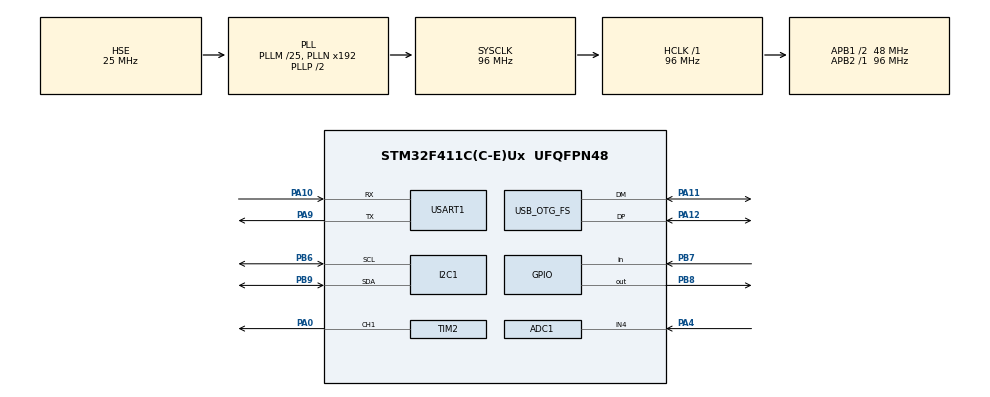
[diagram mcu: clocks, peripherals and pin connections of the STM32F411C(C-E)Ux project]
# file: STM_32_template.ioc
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ADC1.Channel-3\#ChannelRegularConversion=ADC_CHANNEL_4
ADC1.Channel-6\#ChannelInjectedConversion=ADC_CHANNEL_4
ADC1.Channel-7\#ChannelInjectedConversion=ADC_CHANNEL_4
ADC1.Channel-8\#ChannelInjectedConversion=ADC_CHANNEL_4
ADC1.Channel-9\#ChannelInjectedConversion=ADC_CHANNEL_4
ADC1.ContinuousConvMode=ENABLE
ADC1.DMAContinuousRequests=ENABLE
ADC1.DiscontinuousConvMode=DISABLE
ADC1.InjNumberOfConversion=4
ADC1.InjectedOffset-6\#ChannelInjectedConversion=0
ADC1.InjectedOffset-7\#ChannelInjectedConversion=0
ADC1.InjectedOffset-8\#ChannelInjectedConversion=0
ADC1.InjectedOffset-9\#ChannelInjectedConversion=0
ADC1.InjectedRank-6\#ChannelInjectedConversion=1
ADC1.InjectedRank-7\#ChannelInjectedConversion=2
ADC1.InjectedRank-8\#ChannelInjectedConversion=3
ADC1.InjectedRank-9\#ChannelInjectedConversion=4
ADC1.NbrOfConversion=1
ADC1.NbrOfConversionFlag=1
ADC1.Rank-3\#ChannelRegularConversion=1
ADC1.Resolution=ADC_RESOLUTION_12B
ADC1.SamplingTime-3\#ChannelRegularConversion=ADC_SAMPLETIME_3CYCLES
ADC1.SamplingTime-6\#ChannelInjectedConversion=ADC_SAMPLETIME_3CYCLES
ADC1.SamplingTime-7\#ChannelInjectedConversion=ADC_SAMPLETIME_3CYCLES
ADC1.SamplingTime-8\#ChannelInjectedConversion=ADC_SAMPLETIME_3CYCLES
ADC1.SamplingTime-9\#ChannelInjectedConversion=ADC_SAMPLETIME_3CYCLES
ADC1.ScanConvMode=ENABLE
ADC1.master=1
Dma.ADC1.0.Direction=DMA_PERIPH_TO_MEMORY
Dma.ADC1.0.FIFOMode=DMA_FIFOMODE_ENABLE
Dma.ADC1.0.FIFOThreshold=DMA_FIFO_THRESHOLD_FULL
Dma.ADC1.0.Instance=DMA2_Stream0
Dma.ADC1.0.MemBurst=DMA_MBURST_SINGLE
Dma.ADC1.0.MemDataAlignment=DMA_MDATAALIGN_WORD
Dma.ADC1.0.MemInc=DMA_MINC_ENABLE
Dma.ADC1.0.Mode=DMA_CIRCULAR
Dma.ADC1.0.PeriphBurst=DMA_PBURST_SINGLE
Dma.ADC1.0.PeriphDataAlignment=DMA_PDATAALIGN_WORD
Dma.ADC1.0.PeriphInc=DMA_PINC_DISABLE
Dma.ADC1.0.Priority=DMA_PRIORITY_LOW
Dma.Request0=ADC1
Dma.Request1=USART1_TX
Dma.USART1_TX.1.Direction=DMA_MEMORY_TO_PERIPH
Dma.USART1_TX.1.FIFOMode=DMA_FIFOMODE_ENABLE
Dma.USART1_TX.1.FIFOThreshold=DMA_FIFO_THRESHOLD_FULL
Dma.USART1_TX.1.Instance=DMA2_Stream7
Dma.USART1_TX.1.MemBurst=DMA_MBURST_SINGLE
Dma.USART1_TX.1.MemDataAlignment=DMA_MDATAALIGN_BYTE
Dma.USART1_TX.1.MemInc=DMA_MINC_ENABLE
Dma.USART1_TX.1.Mode=DMA_NORMAL
Dma.USART1_TX.1.PeriphBurst=DMA_PBURST_SINGLE
Dma.USART1_TX.1.PeriphDataAlignment=DMA_PDATAALIGN_BYTE
Dma.USART1_TX.1.PeriphInc=DMA_PINC_DISABLE
Dma.USART1_TX.1.Priority=DMA_PRIORITY_LOW
Mcu.Family=STM32F4
Mcu.Name=STM32F411C(C-E)Ux
Mcu.Package=UFQFPN48
NVIC.ADC_IRQn=true\:0\:0\:false\:false\:true\:true\:true\:true
NVIC.DMA2_Stream0_IRQn=true\:0\:0\:false\:false\:true\:false\:true\:true
NVIC.DMA2_Stream7_IRQn=true\:0\:0\:false\:false\:true\:false\:true\:true
NVIC.OTG_FS_IRQn=true\:0\:0\:false\:false\:true\:false\:true\:true
NVIC.PriorityGroup=NVIC_PRIORITYGROUP_4
NVIC.USART1_IRQn=true\:0\:0\:false\:false\:true\:true\:true\:true
PA0-WKUP.Signal=S_TIM2_CH1_ETR
PA10.Mode=Asynchronous
PA10.Signal=USART1_RX
PA11.Mode=Device_Only
PA11.Signal=USB_OTG_FS_DM
PA12.Mode=Device_Only
PA12.Signal=USB_OTG_FS_DP
PA4.Signal=ADCx_IN4
PA9.Mode=Asynchronous
PA9.Signal=USART1_TX
PB6.Mode=I2C
PB6.Signal=I2C1_SCL
PB7.GPIO_PuPd=GPIO_PULLUP
PB7.Signal=GPIO_Input
PB8.Signal=GPIO_Output
PB9.Mode=I2C
PB9.Signal=I2C1_SDA
PH0\ -\ OSC_IN.Mode=HSE-External-Oscillator
PH0\ -\ OSC_IN.Signal=RCC_OSC_IN
PH1\ -\ OSC_OUT.Mode=HSE-External-Oscillator
PH1\ -\ OSC_OUT.Signal=RCC_OSC_OUT
ProjectManager.HeapSize=0x200
ProjectManager.StackSize=0x400
ProjectManager.TargetToolchain=STM32CubeIDE
RCC.48MHZClocksFreq_Value=48000000
RCC.AHBFreq_Value=96000000
RCC.APB1CLKDivider=RCC_HCLK_DIV2
RCC.APB1Freq_Value=48000000
RCC.APB1TimFreq_Value=96000000
RCC.APB2Freq_Value=96000000
RCC.APB2TimFreq_Value=96000000
RCC.CortexFreq_Value=96000000
RCC.HCLKFreq_Value=96000000
RCC.HSE_VALUE=25000000
RCC.HSI_VALUE=16000000
RCC.LSE_VALUE=32768
RCC.PLLM=25
RCC.SYSCLKFreq_VALUE=96000000
RCC.SYSCLKSource=RCC_SYSCLKSOURCE_PLLCLK
RCC.VCOOutputFreq_Value=192000000
SH.ADCx_IN4.0=ADC1_IN4,IN4
SH.S_TIM2_CH1_ETR.0=TIM2_CH1,PWM Generation1 CH1
TIM2.Channel-PWM\ Generation1\ CH1=TIM_CHANNEL_1
TIM2.Period=49
TIM2.Prescaler=95
TIM2.Pulse-PWM\ Generation1\ CH1=500
USART1.Parity=PARITY_NONE
USART1.StopBits=STOPBITS_1
USART1.VirtualMode=VM_ASYNC
USB_DEVICE.CLASS_NAME_FS=CDC
USB_DEVICE.VirtualMode=Cdc
USB_DEVICE.VirtualModeFS=Cdc_FS
USB_OTG_FS.VirtualMode=Device_Only
VP_USB_DEVICE_VS_USB_DEVICE_CDC_FS.Mode=CDC_FS
board=custom

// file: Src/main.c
/* USER CODE BEGIN Header */
/**
  ******************************************************************************
  * @file           : main.c
  * @brief          : Main program body
  ******************************************************************************
  * @attention
  *
  * Copyright (c) 2026 STMicroelectronics.
  * All rights reserved.
  *
  * This software is licensed under terms that can be found in the LICENSE file
  * in the root directory of this software component.
  * If no LICENSE file comes with this software, it is provided AS-IS.
  *
  ******************************************************************************
  */
/* USER CODE END Header */
#include "main.h"
#include "usb_device.h"

/* USER CODE BEGIN Includes */
#include <stdio.h>
#include "app/main_app.h"

/* USER CODE END Includes */

ADC_HandleTypeDef hadc1;
DMA_HandleTypeDef hdma_adc1;

I2C_HandleTypeDef hi2c1;

TIM_HandleTypeDef htim2;

UART_HandleTypeDef huart1;
DMA_HandleTypeDef hdma_usart1_tx;

void SystemClock_Config(void);
static void MX_GPIO_Init(void);
static void MX_DMA_Init(void);
static void MX_ADC1_Init(void);
static void MX_TIM2_Init(void);
static void MX_USART1_UART_Init(void);
static void MX_I2C1_Init(void);

int main(void)
{

  /* MCU Configuration--------------------------------------------------------*/

  /* Reset of all peripherals, Initializes the Flash interface and the Systick. */
  HAL_Init();

  /* Configure the system clock */
  SystemClock_Config();

  /* Initialize all configured peripherals */
  MX_GPIO_Init();
  MX_DMA_Init();
  MX_USB_DEVICE_Init();
  MX_ADC1_Init();
  MX_TIM2_Init();
  MX_USART1_UART_Init();
  MX_I2C1_Init();
  /* USER CODE BEGIN 2 */

   if (main_cpp != NULL)
  {
    main_cpp();
  }

  /* USER CODE END 2 */

  /* Infinite loop */
  /* USER CODE BEGIN WHILE */
  while (1)
  {
    printf("HELLO FROM STM32\r\n");
     HAL_Delay(1000);
    /* USER CODE END WHILE */

  }
}

void SystemClock_Config(void)
{
  RCC_OscInitTypeDef RCC_OscInitStruct = {0};
  RCC_ClkInitTypeDef RCC_ClkInitStruct = {0};

  /** Configure the main internal regulator output voltage
  */
  __HAL_RCC_PWR_CLK_ENABLE();
  __HAL_PWR_VOLTAGESCALING_CONFIG(PWR_REGULATOR_VOLTAGE_SCALE1);

  /** Initializes the RCC Oscillators according to the specified parameters
  * in the RCC_OscInitTypeDef structure.
  */
  RCC_OscInitStruct.OscillatorType = RCC_OSCILLATORTYPE_HSE;
  RCC_OscInitStruct.HSEState = RCC_HSE_ON;
  RCC_OscInitStruct.PLL.PLLState = RCC_PLL_ON;
  RCC_OscInitStruct.PLL.PLLSource = RCC_PLLSOURCE_HSE;
  RCC_OscInitStruct.PLL.PLLM = 25;
  RCC_OscInitStruct.PLL.PLLN = 192;
  RCC_OscInitStruct.PLL.PLLP = RCC_PLLP_DIV2;
  RCC_OscInitStruct.PLL.PLLQ = 4;
  if (HAL_RCC_OscConfig(&RCC_OscInitStruct) != HAL_OK)
  {
    Error_Handler();
  }

  /** Initializes the CPU, AHB and APB buses clocks
  */
  RCC_ClkInitStruct.ClockType = RCC_CLOCKTYPE_HCLK|RCC_CLOCKTYPE_SYSCLK
                              |RCC_CLOCKTYPE_PCLK1|RCC_CLOCKTYPE_PCLK2;
  RCC_ClkInitStruct.SYSCLKSource = RCC_SYSCLKSOURCE_PLLCLK;
  RCC_ClkInitStruct.AHBCLKDivider = RCC_SYSCLK_DIV1;
  RCC_ClkInitStruct.APB1CLKDivider = RCC_HCLK_DIV2;
  RCC_ClkInitStruct.APB2CLKDivider = RCC_HCLK_DIV1;

  if (HAL_RCC_ClockConfig(&RCC_ClkInitStruct, FLASH_LATENCY_3) != HAL_OK)
  {
    Error_Handler();
  }
}

static void MX_ADC1_Init(void)
{

  ADC_ChannelConfTypeDef sConfig = {0};
  ADC_InjectionConfTypeDef sConfigInjected = {0};

  /** Configure the global features of the ADC (Clock, Resolution, Data Alignment and number of conversion)
  */
  hadc1.Instance = ADC1;
  hadc1.Init.ClockPrescaler = ADC_CLOCK_SYNC_PCLK_DIV4;
  hadc1.Init.Resolution = ADC_RESOLUTION_12B;
  hadc1.Init.ScanConvMode = ENABLE;
  hadc1.Init.ContinuousConvMode = ENABLE;
  hadc1.Init.DiscontinuousConvMode = DISABLE;
  hadc1.Init.ExternalTrigConvEdge = ADC_EXTERNALTRIGCONVEDGE_NONE;
  hadc1.Init.ExternalTrigConv = ADC_SOFTWARE_START;
  hadc1.Init.DataAlign = ADC_DATAALIGN_RIGHT;
  hadc1.Init.NbrOfConversion = 1;
  hadc1.Init.DMAContinuousRequests = ENABLE;
  hadc1.Init.EOCSelection = ADC_EOC_SINGLE_CONV;
  if (HAL_ADC_Init(&hadc1) != HAL_OK)
  {
    Error_Handler();
  }

  /** Configure for the selected ADC regular channel its corresponding rank in the sequencer and its sample time.
  */
  sConfig.Channel = ADC_CHANNEL_4;
  sConfig.Rank = 1;
  sConfig.SamplingTime = ADC_SAMPLETIME_3CYCLES;
  if (HAL_ADC_ConfigChannel(&hadc1, &sConfig) != HAL_OK)
  {
    Error_Handler();
  }

  /** Configures for the selected ADC injected channel its corresponding rank in the sequencer and its sample time
  */
  sConfigInjected.InjectedChannel = ADC_CHANNEL_4;
  sConfigInjected.InjectedRank = 1;
  sConfigInjected.InjectedNbrOfConversion = 4;
  sConfigInjected.InjectedSamplingTime = ADC_SAMPLETIME_3CYCLES;
  sConfigInjected.ExternalTrigInjecConvEdge = ADC_EXTERNALTRIGINJECCONVEDGE_NONE;
  sConfigInjected.ExternalTrigInjecConv = ADC_INJECTED_SOFTWARE_START;
  sConfigInjected.AutoInjectedConv = DISABLE;
  sConfigInjected.InjectedDiscontinuousConvMode = DISABLE;
  sConfigInjected.InjectedOffset = 0;
  if (HAL_ADCEx_InjectedConfigChannel(&hadc1, &sConfigInjected) != HAL_OK)
  {
    Error_Handler();
  }

  /** Configures for the selected ADC injected channel its corresponding rank in the sequencer and its sample time
  */
  sConfigInjected.InjectedRank = 2;
  if (HAL_ADCEx_InjectedConfigChannel(&hadc1, &sConfigInjected) != HAL_OK)
  {
    Error_Handler();
  }

  /** Configures for the selected ADC injected channel its corresponding rank in the sequencer and its sample time
  */
  sConfigInjected.InjectedRank = 3;
  if (HAL_ADCEx_InjectedConfigChannel(&hadc1, &sConfigInjected) != HAL_OK)
  {
    Error_Handler();
  }

  /** Configures for the selected ADC injected channel its corresponding rank in the sequencer and its sample time
  */
  sConfigInjected.InjectedRank = 4;
  if (HAL_ADCEx_InjectedConfigChannel(&hadc1, &sConfigInjected) != HAL_OK)
  {
    Error_Handler();
  }

}

static void MX_I2C1_Init(void)
{

  hi2c1.Instance = I2C1;
  hi2c1.Init.ClockSpeed = 100000;
  hi2c1.Init.DutyCycle = I2C_DUTYCYCLE_2;
  hi2c1.Init.OwnAddress1 = 0;
  hi2c1.Init.AddressingMode = I2C_ADDRESSINGMODE_7BIT;
  hi2c1.Init.DualAddressMode = I2C_DUALADDRESS_DISABLE;
  hi2c1.Init.OwnAddress2 = 0;
  hi2c1.Init.GeneralCallMode = I2C_GENERALCALL_DISABLE;
  hi2c1.Init.NoStretchMode = I2C_NOSTRETCH_DISABLE;
  if (HAL_I2C_Init(&hi2c1) != HAL_OK)
  {
    Error_Handler();
  }

}

static void MX_TIM2_Init(void)
{

  TIM_MasterConfigTypeDef sMasterConfig = {0};
  TIM_OC_InitTypeDef sConfigOC = {0};

  htim2.Instance = TIM2;
  htim2.Init.Prescaler = 95;
  htim2.Init.CounterMode = TIM_COUNTERMODE_UP;
  htim2.Init.Period = 49;
  htim2.Init.ClockDivision = TIM_CLOCKDIVISION_DIV1;
  htim2.Init.AutoReloadPreload = TIM_AUTORELOAD_PRELOAD_DISABLE;
  if (HAL_TIM_PWM_Init(&htim2) != HAL_OK)
  {
    Error_Handler();
  }
  sMasterConfig.MasterOutputTrigger = TIM_TRGO_RESET;
  sMasterConfig.MasterSlaveMode = TIM_MASTERSLAVEMODE_DISABLE;
  if (HAL_TIMEx_MasterConfigSynchronization(&htim2, &sMasterConfig) != HAL_OK)
  {
    Error_Handler();
  }
  sConfigOC.OCMode = TIM_OCMODE_PWM1;
  sConfigOC.Pulse = 500;
  sConfigOC.OCPolarity = TIM_OCPOLARITY_HIGH;
  sConfigOC.OCFastMode = TIM_OCFAST_DISABLE;
  if (HAL_TIM_PWM_ConfigChannel(&htim2, &sConfigOC, TIM_CHANNEL_1) != HAL_OK)
  {
    Error_Handler();
  }
  HAL_TIM_MspPostInit(&htim2);

}

static void MX_USART1_UART_Init(void)
{

  huart1.Instance = USART1;
  huart1.Init.BaudRate = 115200;
  huart1.Init.WordLength = UART_WORDLENGTH_8B;
  huart1.Init.StopBits = UART_STOPBITS_1;
  huart1.Init.Parity = UART_PARITY_NONE;
  huart1.Init.Mode = UART_MODE_TX_RX;
  huart1.Init.HwFlowCtl = UART_HWCONTROL_NONE;
  huart1.Init.OverSampling = UART_OVERSAMPLING_16;
  if (HAL_UART_Init(&huart1) != HAL_OK)
  {
    Error_Handler();
  }

}

static void MX_DMA_Init(void)
{

  /* DMA controller clock enable */
  __HAL_RCC_DMA2_CLK_ENABLE();

  /* DMA interrupt init */
  /* DMA2_Stream0_IRQn interrupt configuration */
  HAL_NVIC_SetPriority(DMA2_Stream0_IRQn, 0, 0);
  HAL_NVIC_EnableIRQ(DMA2_Stream0_IRQn);
  /* DMA2_Stream7_IRQn interrupt configuration */
  HAL_NVIC_SetPriority(DMA2_Stream7_IRQn, 0, 0);
  HAL_NVIC_EnableIRQ(DMA2_Stream7_IRQn);

}

static void MX_GPIO_Init(void)
{
  GPIO_InitTypeDef GPIO_InitStruct = {0};

  /* GPIO Ports Clock Enable */
  __HAL_RCC_GPIOH_CLK_ENABLE();
  __HAL_RCC_GPIOA_CLK_ENABLE();
  __HAL_RCC_GPIOB_CLK_ENABLE();

  /*Configure GPIO pin Output Level */
  HAL_GPIO_WritePin(GPIOB, GPIO_PIN_8, GPIO_PIN_RESET);

  /*Configure GPIO pin : PB7 */
  GPIO_InitStruct.Pin = GPIO_PIN_7;
  GPIO_InitStruct.Mode = GPIO_MODE_INPUT;
  GPIO_InitStruct.Pull = GPIO_PULLUP;
  HAL_GPIO_Init(GPIOB, &GPIO_InitStruct);

  /*Configure GPIO pin : PB8 */
  GPIO_InitStruct.Pin = GPIO_PIN_8;
  GPIO_InitStruct.Mode = GPIO_MODE_OUTPUT_PP;
  GPIO_InitStruct.Pull = GPIO_NOPULL;
  GPIO_InitStruct.Speed = GPIO_SPEED_FREQ_LOW;
  HAL_GPIO_Init(GPIOB, &GPIO_InitStruct);

}

void Error_Handler(void)
{
  __disable_irq();
  while (1)
  {
  }
}
